# RockChip_RK3588 register map
Vendor: RockChip Electronics Co., Ltd.; Series: RK3588; File version: 0.1
Registers are 32-bit, read-write, no defined reset value unless marked. A register's access mark holds for its fields unless they carry their own. Offsets are from the block's base; [hi:lo] are bit positions; <NAME> marks a mode.

## CRU_BIGCORE1
Base 0xFD812000
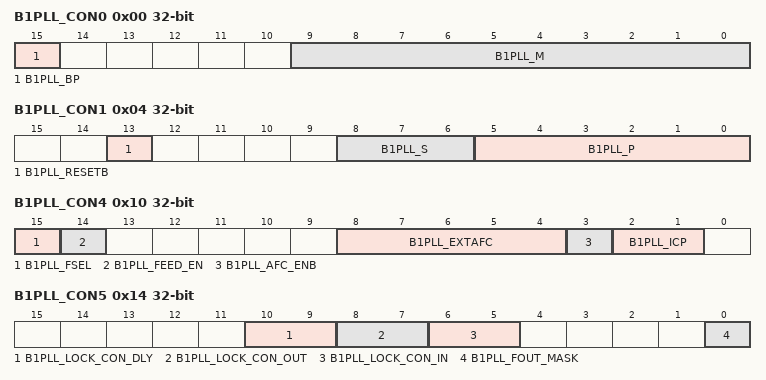
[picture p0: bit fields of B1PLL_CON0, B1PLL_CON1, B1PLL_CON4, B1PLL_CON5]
0x00 B1PLL_CON0 — B1PLL configuration register 0
  [15] B1PLL_BP — BYPASS: Bypass mode control signal.
    1=BYPASS (bypass mode is enabled. (FOUT = FIN).); 0=NORMAL (PLL operates normally.)
  [9:0] B1PLL_M — M: Division value of the 10-bit programmable main-divider. PLL has to be reset if M value is changed. 64 <= pll_m <= 1023
0x04 B1PLL_CON1 — B1PLL configuration register 1
  [13] B1PLL_RESETB — RESETB: Power down control signal.
    0=NORMAL (RESETB=0 from 1, PLL starts its normal operation after lock time.); 1=POWER_DOWN (RESETB=1, power down mode is enabled and all digital blocks are reset.)
  [8:6] B1PLL_S — Division value of the 3-bit programmable scaler. 0 <= pll_s <= 6
  [5:0] B1PLL_P — P: Division value of the 6-bit programmable pre-divider. PLL has to be reset if P value is changed. 1 <= pll_p <= 63
0x10 B1PLL_CON4 — B1PLL configuration register 4
  [15] B1PLL_FSEL — FSEL: Monitoring pin.
    0=FREF (FEED_OUT = FREF.); 1=FEED (FEED_OUT = FEED.)
  [14] B1PLL_FEED_EN — FEED_EN: Monitoring pin.
    0=DISABLED (FEED_OUT is disabled.); 1=ENABLED (FEED_OUT is enabled.)
  [8:4] B1PLL_EXTAFC — EXTAFC: Monitoring pin. If pll_afc_enb=1, AFC is disabled and VCO is calibrated manually by pll_extafc[4:0] for the test of VCO range.
  [3] B1PLL_AFC_ENB — AFC_ENB: Monitoring pin.
    0=ENABLED (AFC is enabled and VCO is calibrated automatically.); 1=DISABLED (AFC is disabled and VCO is calibrated manually by pll_extafc[4:0] for the test of VCO range.)
  [2:1] B1PLL_ICP — Charge-pump current control signal.
0x14 B1PLL_CON5 — B1PLL configuration register 5
  [10:9] B1PLL_LOCK_CON_DLY — LOCK_CON_DLY: Lock detector setting of the detection resolution.
  [8:7] B1PLL_LOCK_CON_OUT — LOCK_CON_OUT: Lock detector setting of the output margin.
  [6:5] B1PLL_LOCK_CON_IN — LOCK_CON_IN: Lock detector setting of the input margin.
  [0] B1PLL_FOUT_MASK — FOUT_MASK: Scaler's re-initialization time control pin.
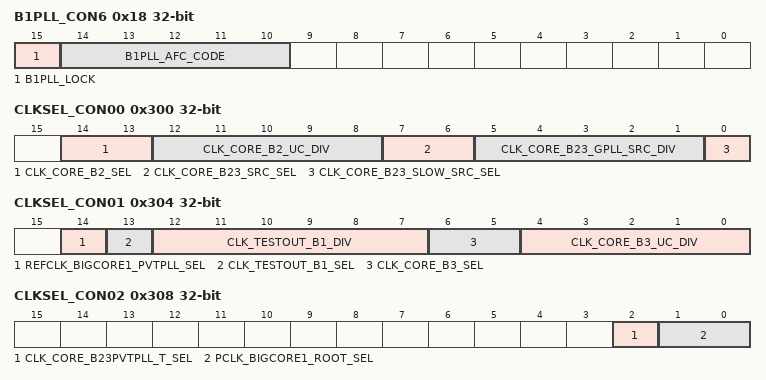
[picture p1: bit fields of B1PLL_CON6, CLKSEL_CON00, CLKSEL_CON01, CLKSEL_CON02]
0x18 B1PLL_CON6 — B1PLL configuration register 6
  [15] B1PLL_LOCK — LOCK: PLL lock flag.
    0=UNLOCKED (PLL is unlocked.); 1=LOCKED (PLL is locked.)
  [14:10] B1PLL_AFC_CODE — AFC_CODE: Monitoring pin. Output code of AFC(5 bits).
0x280 MODE_CON00 — Internal PLL mode select register
  [1:0] CLK_B1PLL_MODE — clk_b1pll_mux clock mux.
    0=XIN_OSC0_FUNC; 1=CLK_B1PLL; 2=CLK_DEEPSLOW
0x300 CLKSEL_CON00 — Internal clock select and division register 0
  [14:13] CLK_CORE_B2_SEL — clk_core_b2 clock mux.
    0=CLK_CORE_B2_UC; 1=CLK_CORE_B2_CLEAN; 2=CLK_CORE_B23_PVTPLL_T
  [12:8] CLK_CORE_B2_UC_DIV — Divide clk_core_b2_uc by (div_con + 1).
  [7:6] CLK_CORE_B23_SRC_SEL — clk_core_b23_src clock mux.
    0=CLK_CORE_B23_SLOW_SRC; 1=CLK_CORE_B23_GPLL_SRC; 2=CLK_B1PLL
  [5:1] CLK_CORE_B23_GPLL_SRC_DIV — Divide clk_core_b23_gpll_src by (div_con + 1).
  [0] CLK_CORE_B23_SLOW_SRC_SEL — clk_core_b23_slow_src clock mux.
    0=XIN_OSC0_FUNC; 1=CLK_DEEPSLOW
0x304 CLKSEL_CON01 — Internal clock select and division register 1
  [14] REFCLK_BIGCORE1_PVTPLL_SEL — refclk_bigcore1_pvtpll clock mux.
    0=CLK_CORE_B23; 1=XIN_OSC0_FUNC
  [13] CLK_TESTOUT_B1_SEL — clk_testout_b1 clock mux.
    0=CLK_B1PLL; 1=CLK_CORE_B23_PVTPLL
  [12:7] CLK_TESTOUT_B1_DIV — Divide clk_testout_b1 by (div_con + 1).
  [6:5] CLK_CORE_B3_SEL — clk_core_b3 clock mux.
    0=CLK_CORE_B3_UC; 1=CLK_CORE_B3_CLEAN; 2=CLK_CORE_B23_PVTPLL_T
  [4:0] CLK_CORE_B3_UC_DIV — Divide clk_core_b3_uc by (div_con + 1).
0x308 CLKSEL_CON02 — Internal clock select and division register 2
  [2] CLK_CORE_B23PVTPLL_T_SEL — clk_core_b23pvtpll_t clock mux.
    0=CLK_DEEPSLOW; 1=CLK_CORE_B23PVTPLL
  [1:0] PCLK_BIGCORE1_ROOT_SEL — pclk_bigcore1_root clock mux.
    0=CLK_MATRIX_100M_SRC; 1=CLK_MATRIX_50M_SRC; 2=XIN_OSC0_FUNC
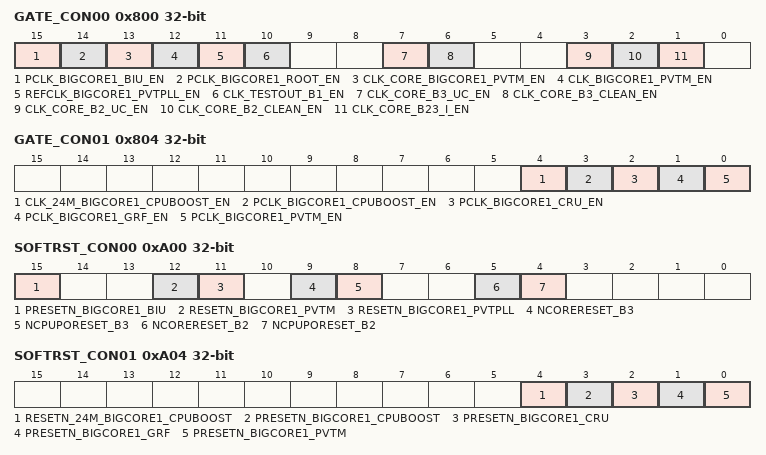
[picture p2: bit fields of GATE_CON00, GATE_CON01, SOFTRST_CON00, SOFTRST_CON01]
0x800 GATE_CON00 — Internal clock gate and division register 0
  [all] fields
    0=ENABLE; 1=DISABLE
  [15] PCLK_BIGCORE1_BIU_EN — pclk_bigcore1_biu clock gating control.
  [14] PCLK_BIGCORE1_ROOT_EN — pclk_bigcore1_root clock gating control.
  [13] CLK_CORE_BIGCORE1_PVTM_EN — clk_core_bigcore1_pvtm clock gating control.
  [12] CLK_BIGCORE1_PVTM_EN — clk_bigcore1_pvtm clock gating control.
  [11] REFCLK_BIGCORE1_PVTPLL_EN — refclk_bigcore1_pvtpll clock gating control.
  [10] CLK_TESTOUT_B1_EN — clk_testout_b1 clock gating control.
  [7] CLK_CORE_B3_UC_EN — clk_core_b3_uc clock gating control.
  [6] CLK_CORE_B3_CLEAN_EN — clk_core_b3_clean clock gating control.
  [3] CLK_CORE_B2_UC_EN — clk_core_b2_uc clock gating control.
  [2] CLK_CORE_B2_CLEAN_EN — clk_core_b2_clean clock gating control.
  [1] CLK_CORE_B23_I_EN — clk_core_b23_i clock gating control.
0x804 GATE_CON01 — Internal clock gate and division register 1
  [all] fields
    0=ENABLE; 1=DISABLE
  [4] CLK_24M_BIGCORE1_CPUBOOST_EN — clk_24m_bigcore1_cpuboost clock gating control.
  [3] PCLK_BIGCORE1_CPUBOOST_EN — pclk_bigcore1_cpuboost clock gating control.
  [2] PCLK_BIGCORE1_CRU_EN — pclk_bigcore1_cru clock gating control.
  [1] PCLK_BIGCORE1_GRF_EN — pclk_bigcore1_grf clock gating control.
  [0] PCLK_BIGCORE1_PVTM_EN — pclk_bigcore1_pvtm clock gating control.
0xA00 SOFTRST_CON00 — Internal clock reset register 0
  [15] PRESETN_BIGCORE1_BIU — When high, reset relative logic
  [12] RESETN_BIGCORE1_PVTM — When high, reset relative logic
  [11] RESETN_BIGCORE1_PVTPLL — When high, reset relative logic
  [9] NCORERESET_B3 — When high, reset relative logic
  [8] NCPUPORESET_B3 — When high, reset relative logic
  [5] NCORERESET_B2 — When high, reset relative logic
  [4] NCPUPORESET_B2 — When high, reset relative logic
0xA04 SOFTRST_CON01 — Internal clock reset register 1
  [4] RESETN_24M_BIGCORE1_CPUBOOST — When high, reset relative logic
  [3] PRESETN_BIGCORE1_CPUBOOST — When high, reset relative logic
  [2] PRESETN_BIGCORE1_CRU — When high, reset relative logic
  [1] PRESETN_BIGCORE1_GRF — When high, reset relative logic
  [0] PRESETN_BIGCORE1_PVTM — When high, reset relative logic
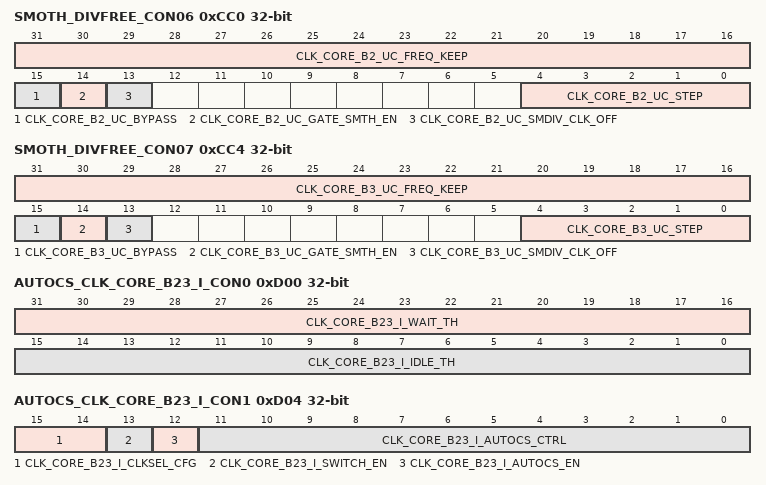
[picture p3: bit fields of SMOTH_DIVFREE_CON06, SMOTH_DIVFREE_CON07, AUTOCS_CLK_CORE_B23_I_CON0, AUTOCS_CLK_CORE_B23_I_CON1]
0xCC0 SMOTH_DIVFREE_CON06 — Smoothdiv control register
  [31:16] CLK_CORE_B2_UC_FREQ_KEEP — freq_keep Cycles to keep every step.
  [15] CLK_CORE_B2_UC_BYPASS — bypass Division signal bypass.
    1=BYPASS; 0=USE (Use Smoothdiv to control clock division.)
  [14] CLK_CORE_B2_UC_GATE_SMTH_EN — gate_smth_en If trigger smoothdiv function when clk been gated.
    1=ENABLE; 0=DISABLE
  [13] CLK_CORE_B2_UC_SMDIV_CLK_OFF — smdiv_clk_off Turn off smoothdiv module clk.
    1=TURN_OFF; 0=TURN_ON
  [4:0] CLK_CORE_B2_UC_STEP — step Step of div from 0x1f to setting configuration .
0xCC4 SMOTH_DIVFREE_CON07 — Smoothdiv control register
  [31:16] CLK_CORE_B3_UC_FREQ_KEEP — freq_keep Cycles to keep every step.
  [15] CLK_CORE_B3_UC_BYPASS — bypass Division signal bypass.
    1=BYPASS; 0=USE (Use Smoothdiv to control clock division.)
  [14] CLK_CORE_B3_UC_GATE_SMTH_EN — gate_smth_en If trigger smoothdiv function when clk been gated.
    1=ENABLE; 0=DISABLE
  [13] CLK_CORE_B3_UC_SMDIV_CLK_OFF — smdiv_clk_off Turn off smoothdiv module clk.
    1=TURN_OFF; 0=TURN_ON
  [4:0] CLK_CORE_B3_UC_STEP — step Step of div from 0x1f to setting configuration .
0xD00 AUTOCS_CLK_CORE_B23_I_CON0 — Auto clock switch control register 0
  [31:16] CLK_CORE_B23_I_WAIT_TH — wait_th. Wait time threshold, measured by original clk.
  [15:0] CLK_CORE_B23_I_IDLE_TH — idle_th. Idle time threshold, measured by original clk.
0xD04 AUTOCS_CLK_CORE_B23_I_CON1 — Auto clock switch control register 1
  [15:14] CLK_CORE_B23_I_CLKSEL_CFG — clksel_cfg Auto switch clock selection.
    0=ORIGINAL_CLK; 1=XIN_OSC0_FUNC_DIV; 2=CLK_RTC_32K
  [13] CLK_CORE_B23_I_SWITCH_EN — switch_en
    1=ENABLE (Enable clk_core_b23_i switched to lower frequency when module is inactive.); 0=DISABLE (Disable auto switch function.)
  [12] CLK_CORE_B23_I_AUTOCS_EN — autocs_en
    1=ENABLE (Enable clk_core_b23_i switch to lower frequency.); 0=DISABLE
  [11:0] CLK_CORE_B23_I_AUTOCS_CTRL — autocs_ctrl. Others: Reserved.
    0xFFF=ENABLE (Enable clk_core_b23_i switch to lower frequency.); 0=DISABLE
